VERSION ""

NS_ :

BS_:

BU_: XXX

BO_ 417018865 NEW_MSG_1: 8 XXX

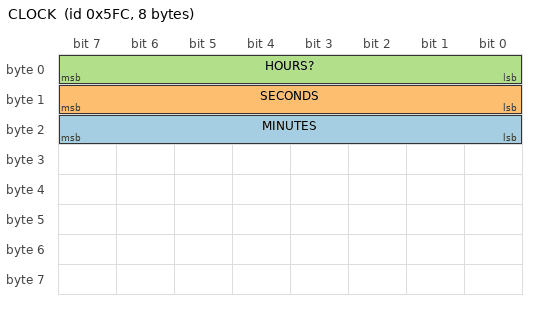
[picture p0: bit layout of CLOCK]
BO_ 1532 CLOCK: 8 XXX
 SG_ MINUTES : 23|8@0+ (1,0) [0|255] "" XXX
 SG_ SECONDS : 15|8@0+ (1,0) [0|255] "" XXX
 SG_ HOURS? : 7|8@0+ (1,0) [0|255] "" XXX
